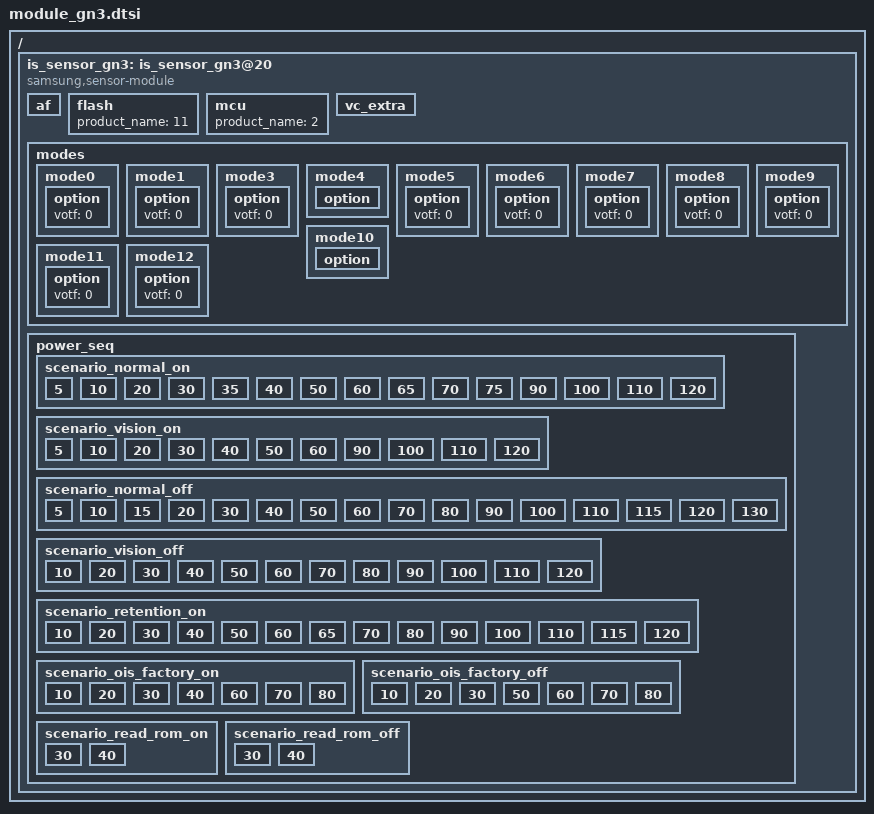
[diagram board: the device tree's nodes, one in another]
/*
 * SAMSUNG EXYNOSxxxx board camera device tree source
 *
 * Copyright (c) 2019 Samsung Electronics Co., Ltd.
 *		http://www.samsung.com
 *
 * This program is free software; you can redistribute it and/or modify
 * it under the terms of the GNU General Public License version 2 as
 * published by the Free Software Foundation.
 */

#include <dt-bindings/camera/exynos_is_dt.h>

/ {
	fragment@camera {
		target-path = "/";
		__overlay__ {
			is_sensor_gn3: is_sensor_gn3@20 {
				compatible = "samsung,sensor-module";

				/* common */
				sensor_id = <SENSOR_NAME_S5KGN3>;
				active_width = <8160>;
				active_height = <6144>;
				margin_left = <0>;
				margin_right = <0>;
				margin_top = <0>;
				margin_bottom = <0>;
				max_framerate = <480>;
				bitwidth = <10>;
				use_retention_mode = <SENSOR_RETENTION_INACTIVE>;
				sensor_maker = "SLSI";
				sensor_name = "S5KGN3";
				setfile_name = "setfile_gn3.bin";

				status = "okay";

				/* board */
				pinctrl-names = "pin0", "pin1", "pin2", "release";
				pinctrl-0 = <>;
				pinctrl-1 = <&sensor_mclk2_out>;
				pinctrl-2 = <&sensor_mclk2_fn>;
				pinctrl-3 = <>;

				position = <0>;	/* Rear:0. Front:1. Rear_sub:2. Secure:3. */
				id = <0>; /* is_sensor id */
				mclk_ch = <2>;
				mclk_freq = <19200>;
				sensor_i2c_ch = <0>; /* SENSOR_CONTROL_I2C0 */

				/* vendor */
				rom_type = <2>; /* ROM_TYPE_EEPROM */
				rom_id = <0>;
				rom_cal_index = <0>;

				/* peri */
				af {
					product_name = <18>; /* ACTUATOR_NAME_AK737X */
					i2c_ch = <1>; /* SENSOR_CONTROL_I2C1 */
				};

				flash {
					product_name = <11>; /* FLASH_GPIO */
				};

				mcu {
					product_name = <2>; /* INTERNAL */
				};

				vc_extra {
					/* ex) statX = <stat_type, sensor_mode, max_width, max_height, max_element> */
					stat0 = </* not available */>;									/* VC_BUF_DATA_TYPE_SENSOR_STAT1 */
					stat1 = </*VC_STAT_TYPE_PDP_4_0_PDAF_STAT0*/ 1100 /*VC_SENSOR_MODE_2PD_MODE3*/ 102 4080 764 2>;	/* VC_BUF_DATA_TYPE_GENERAL_STAT1 */
					stat2 = </* not available */>;									/* VC_BUF_DATA_TYPE_SENSOR_STAT2 */
					stat3 = </*VC_STAT_TYPE_PDP_4_0_PDAF_STAT1*/ 1101 /*VC_SENSOR_MODE_2PD_MODE3*/ 102 4080 764 2>;	/* VC_BUF_DATA_TYPE_GENERAL_STAT2 */
				};

				/* sensor modes
				*	SENSOR_GN3_8160X6120_27FPS = 0,
				*	SENSOR_GN3_4896X3672_30FPS_RAW12 = 1,
				*	SENSOR_GN3_7680X4320_30FPS = 2,
				*	SENSOR_GN3_7680X4320_30FPS_MPC = 3,
				*	SENSOR_GN3_4080X3060_60FPS_RAW12_FRO = 4,
				*	SENSOR_GN3_4080X3060_60FPS_RAW12 = 5,
				*	SENSOR_GN3_3328X1872_120FPS = 6,
				*	SENSOR_GN3_4080X2296_60FPS_RAW12 = 7,
				*	SENSOR_GN3_2040X1148_240FPS = 8,
				*	SENSOR_GN3_2040X1148_480FPS_MODE2 = 9,
				*	SENSOR_GN3_2040X1532_120FPS = 10,
				*	SENSOR_GN3_2800X2100_60FPS = 11,
				*	SENSOR_GN3_4080X2720_60FPS_RAW12 = 12,
				*/
				modes {
						/* common = <width, height, fps, settle, mode, lane, speed, interleave, lrte, pd_mode> */
						/* vcX = <map, hwformat, width, height, hwformat, type, width, height> */
					mode0 {
						common = <8160 6120 27 0 0 CSI_DATA_LANES_3 3046 CSI_MODE_VC_DT LRTE_ENABLE PD_MOD3>;
						vc0 = </* in */ 0 HW_FORMAT_RAW10 8160 6120	/* out */ HW_FORMAT_RAW10 VC_NOTHING 8160 6120>;
						vc1 = </* in */ 1 HW_FORMAT_UNKNOWN 0 0		/* out */ HW_FORMAT_UNKNOWN VC_NOTHING 0 0>;
						vc2 = </* in */ 2 HW_FORMAT_RAW10 4080 764	/* out */ HW_FORMAT_RAW10 VC_NOTHING 0 0>;
						vc3 = </* in */ 3 HW_FORMAT_UNKNOWN 0 0		/* out */ HW_FORMAT_UNKNOWN VC_NOTHING 0 0>;
						option { votf = <0>; };
					};

					mode1 {
						common = <4896 3672 30 0 1 CSI_DATA_LANES_3 3315 CSI_MODE_VC_DT LRTE_ENABLE PD_MOD3>;
						vc0 = </* in */ 0 HW_FORMAT_RAW12 4896 3672	/* out */ HW_FORMAT_RAW12 VC_NOTHING 4896 3672>;
						vc1 = </* in */ 1 HW_FORMAT_UNKNOWN 0 0		/* out */ HW_FORMAT_UNKNOWN VC_NOTHING 0 0>;
						vc2 = </* in */ 2 HW_FORMAT_RAW10 2448 458	/* out */ HW_FORMAT_RAW10 VC_NOTHING 0 0>;
						vc3 = </* in */ 3 HW_FORMAT_UNKNOWN 0 0		/* out */ HW_FORMAT_UNKNOWN VC_NOTHING 0 0>;
						option { votf = <0>; };
					};

					mode3 { /* MPC */
						common = <7680 4320 30 0 3 CSI_DATA_LANES_3 2585 CSI_MODE_VC_DT LRTE_DISABLE PD_MOD3>;
						vc0 = </* in */ 0 HW_FORMAT_RAW10 7680 4320	/* out */ HW_FORMAT_RAW10 VC_NOTHING 7680 4320>;
						vc1 = </* in */ 1 HW_FORMAT_UNKNOWN 0 0		/* out */ HW_FORMAT_UNKNOWN VC_NOTHING 0 0>;
						vc2 = </* in */ 2 HW_FORMAT_RAW10 3840 540	/* out */ HW_FORMAT_RAW10 VC_NOTHING 0 0>;
						vc3 = </* in */ 3 HW_FORMAT_UNKNOWN 0 0		/* out */ HW_FORMAT_UNKNOWN VC_NOTHING 0 0>;
						option { votf = <0>; };
					};

					mode4 { /* FRO */
						common = <4080 3060 60 0 4 CSI_DATA_LANES_3 3315 CSI_MODE_VC_DT LRTE_ENABLE PD_MOD3 EX_12BIT>;
						vc0 = </* in */ 0 HW_FORMAT_RAW12 4080 3060	/* out */ HW_FORMAT_RAW12 VC_NOTHING 4080 3060>;
						vc1 = </* in */ 1 HW_FORMAT_UNKNOWN 0 0		/* out */ HW_FORMAT_UNKNOWN VC_NOTHING 0 0>;
						vc2 = </* in */ 2 HW_FORMAT_RAW10 4080 764	/* out */ HW_FORMAT_RAW10 VC_NOTHING 0 0>;
						vc3 = </* in */ 3 HW_FORMAT_UNKNOWN 0 0		/* out */ HW_FORMAT_UNKNOWN VC_NOTHING 0 0>;
						option { votf = <0>; vvalid_time = <8736>; req_vvalid_time = <10000>; };// mpc_mode = <2> };
					};

					mode5 {
						common = <4080 3060 60 0 5 CSI_DATA_LANES_3 3315 CSI_MODE_VC_DT LRTE_ENABLE PD_MOD3>;
						vc0 = </* in */ 0 HW_FORMAT_RAW10 4080 3060	/* out */ HW_FORMAT_RAW10 VC_NOTHING 4080 3060>;
						vc1 = </* in */ 1 HW_FORMAT_UNKNOWN 0 0		/* out */ HW_FORMAT_UNKNOWN VC_NOTHING 0 0>;
						vc2 = </* in */ 2 HW_FORMAT_RAW10 4080 764	/* out */ HW_FORMAT_RAW10 VC_NOTHING 0 0>;
						vc3 = </* in */ 3 HW_FORMAT_UNKNOWN 0 0		/* out */ HW_FORMAT_UNKNOWN VC_NOTHING 0 0>;
						option { votf = <0>; };
					};

					mode6 {
						common = <3328 1872 120 0 6 CSI_DATA_LANES_3 3046 CSI_MODE_VC_DT LRTE_ENABLE PD_MOD3>;
						vc0 = </* in */ 0 HW_FORMAT_RAW10 3328 1872	/* out */ HW_FORMAT_RAW10 VC_NOTHING 3328 1872>;
						vc1 = </* in */ 1 HW_FORMAT_UNKNOWN 0 0		/* out */ HW_FORMAT_UNKNOWN VC_NOTHING 0 0>;
						vc2 = </* in */ 2 HW_FORMAT_RAW10 3328 468	/* out */ HW_FORMAT_RAW10 VC_NOTHING 0 0>;
						vc3 = </* in */ 3 HW_FORMAT_UNKNOWN 0 0		/* out */ HW_FORMAT_UNKNOWN VC_NOTHING 0 0>;
						option { votf = <0>; };
					};

					mode7 {
						common = <4080 2296 60 0 7 CSI_DATA_LANES_3 3315 CSI_MODE_VC_DT LRTE_ENABLE PD_MOD3>;
						vc0 = </* in */ 0 HW_FORMAT_RAW12 4080 2296	/* out */ HW_FORMAT_RAW12 VC_NOTHING 4080 2296>;
						vc1 = </* in */ 1 HW_FORMAT_UNKNOWN 0 0		/* out */ HW_FORMAT_UNKNOWN VC_NOTHING 0 0>;
						vc2 = </* in */ 2 HW_FORMAT_RAW10 4080 574	/* out */ HW_FORMAT_RAW10 VC_NOTHING 0 0>;
						vc3 = </* in */ 3 HW_FORMAT_UNKNOWN 0 0		/* out */ HW_FORMAT_UNKNOWN VC_NOTHING 0 0>;
						option { votf = <0>; };
					};

					mode8 {
						common = <2040 1148 240 0 8 CSI_DATA_LANES_3 2585 CSI_MODE_VC_DT LRTE_ENABLE PD_MOD3>;
						vc0 = </* in */ 0 HW_FORMAT_RAW10 2040 1148	/* out */ HW_FORMAT_RAW10 VC_NOTHING 2040 1148>;
						vc1 = </* in */ 1 HW_FORMAT_UNKNOWN 0 0		/* out */ HW_FORMAT_UNKNOWN VC_NOTHING 0 0>;
						vc2 = </* in */ 2 HW_FORMAT_RAW10 2032 286	/* out */ HW_FORMAT_RAW10 VC_NOTHING 0 0>;
						vc3 = </* in */ 3 HW_FORMAT_UNKNOWN 0 0		/* out */ HW_FORMAT_UNKNOWN VC_NOTHING 0 0>;
						option { votf = <0>; };
					};

					mode9 {
						common = <2040 1148 480 0 9 CSI_DATA_LANES_3 2585 CSI_MODE_VC_DT LRTE_ENABLE PD_MOD2>;
						vc0 = </* in */ 0 HW_FORMAT_RAW10 2040 1148	/* out */ HW_FORMAT_RAW10 VC_NOTHING 2040 1148>;
						vc1 = </* in */ 1 HW_FORMAT_UNKNOWN 0 0		/* out */ HW_FORMAT_UNKNOWN VC_NOTHING 0 0>;
						vc2 = </* in */ 2 HW_FORMAT_UNKNOWN 0 0		/* out */ HW_FORMAT_UNKNOWN VC_NOTHING 0 0>;
						vc3 = </* in */ 3 HW_FORMAT_UNKNOWN 0 0		/* out */ HW_FORMAT_UNKNOWN VC_NOTHING 0 0>;
						option { votf = <0>; };
					};

					mode10 {
						common = <2040 1532 120 0 10 CSI_DATA_LANES_3 2585 CSI_MODE_VC_DT LRTE_ENABLE PD_NONE>;
						vc0 = </* in */ 0 HW_FORMAT_RAW10 2040 1532	/* out */ HW_FORMAT_RAW10 VC_NOTHING 2040 1532>;
						vc1 = </* in */ 1 HW_FORMAT_UNKNOWN 0 0		/* out */ HW_FORMAT_UNKNOWN VC_NOTHING 0 0>;
						vc2 = </* in */ 2 HW_FORMAT_UNKNOWN 0 0		/* out */ HW_FORMAT_UNKNOWN VC_NOTHING 0 0>;
						vc3 = </* in */ 3 HW_FORMAT_UNKNOWN 0 0		/* out */ HW_FORMAT_UNKNOWN VC_NOTHING 0 0>;
						option { votf = <0>; special_mode = <IS_SPECIAL_MODE_FASTAE>; };
					};

					mode11 {
						common = <2800 2100 60 0 11 CSI_DATA_LANES_3 3046 CSI_MODE_VC_DT LRTE_ENABLE PD_MOD3>;
						vc0 = </* in */ 0 HW_FORMAT_RAW10 2800 2100	/* out */ HW_FORMAT_RAW10 VC_NOTHING 2800 2100>;
						vc1 = </* in */ 1 HW_FORMAT_UNKNOWN 0 0		/* out */ HW_FORMAT_UNKNOWN VC_NOTHING 0 0>;
						vc2 = </* in */ 2 HW_FORMAT_RAW10 2800 524	/* out */ HW_FORMAT_RAW10 VC_NOTHING 0 0>;
						vc3 = </* in */ 3 HW_FORMAT_UNKNOWN 0 0		/* out */ HW_FORMAT_UNKNOWN VC_NOTHING 0 0>;
						option { votf = <0>; };
					};

					mode12 {
						common = <4080 2720 60 0 12 CSI_DATA_LANES_3 3315 CSI_MODE_VC_DT LRTE_ENABLE PD_MOD3>;
						vc0 = </* in */ 0 HW_FORMAT_RAW12 4080 2720	/* out */ HW_FORMAT_RAW12 VC_NOTHING 4080 2720>;
						vc1 = </* in */ 1 HW_FORMAT_UNKNOWN 0 0		/* out */ HW_FORMAT_UNKNOWN VC_NOTHING 0 0>;
						vc2 = </* in */ 2 HW_FORMAT_RAW10 4080 680	/* out */ HW_FORMAT_RAW10 VC_NOTHING 0 0>;
						vc3 = </* in */ 3 HW_FORMAT_UNKNOWN 0 0		/* out */ HW_FORMAT_UNKNOWN VC_NOTHING 0 0>;
						option { votf = <0>; };
					};
				};



				power_seq {
					use = <1>;
					gpio_mclk = <&gpg1 2 0x1>;
					scenario_normal_on {
						sensor_scenario = <SENSOR_SCENARIO_NORMAL>;
						gpio_scenario = <GPIO_SCENARIO_ON>;

						/* A start node number should be over the 10 for reserved number 0~9. */
						/* pname = "name"; pin = <act value delay voltage>; gpio = <gpx# # 0x1>; */
						5 { pname = "S2MPB02_BUCK2"; pin = <PIN_REGULATOR 1 0>; share = <SRT_ACQUIRE SHARED_PIN0 1>; };
						10 { pname = "sen_rst low"; pin = <PIN_OUTPUT 0 0>; gpio = <&gpc0 0 0x1>; };
						20 { pname = "VDDD_2.8V_OIS"; pin = <PIN_REGULATOR 1 300>; };
						30 { pname = "VDDIO_1.8V_CAM"; pin = <PIN_REGULATOR 1 0>; share = <SRT_ACQUIRE SHARED_PIN2 1>; };
						35 { pname = "VDDIO_1.8V_SUB"; pin = <PIN_REGULATOR 1 0>; share = <SRT_ACQUIRE SHARED_PIN1 1>; };
						40 { pname = "VDDPHY_1.05V_CAM"; pin = <PIN_REGULATOR 1 0>; };
						50 { pname = "S2MPB02_BUCK1"; pin = <PIN_REGULATOR 1 1>; };
						60 { pname = "VDDAF_COMMON_CAM"; pin = <PIN_REGULATOR 1 1>; share = <SRT_ACQUIRE SHARED_PIN4 1>; };
						65 { pname = "VDDAF_2.8V_SUB"; pin = <PIN_REGULATOR 1 0>; share = <SRT_ACQUIRE SHARED_PIN5 1>; };
						70 { pname = "VDDA_2.8V_CAM"; pin = <PIN_REGULATOR 1 100>; share = <SRT_ACQUIRE SHARED_PIN6 1>; };
						75 { pname = "S2MPB02_LD10"; pin = <PIN_REGULATOR 1 0>; share = <SRT_ACQUIRE SHARED_PIN7 1>; };
						//80 { pname = "VDDOIS_2.8V_SUB"; pin = <PIN_REGULATOR 1 0>; share = <SRT_ACQUIRE SHARED_PIN3 1>; };

						90 { pname = "on_i2c"; pin = <PIN_I2C 1 0>; };
						100 { pname = "pin"; pin = <PIN_FUNCTION 2 0>; };
						110 { pname = "MCLK"; pin = <PIN_MCLK 1 1500>; };
						120 { pname = "sen_rst high"; pin = <PIN_OUTPUT 1 3000>; gpio = <&gpc0 0 0x1>; };
					};

					scenario_vision_on {
						sensor_scenario = <SENSOR_SCENARIO_VISION>;
						gpio_scenario = <GPIO_SCENARIO_ON>;

						/* A start node number should be over the 10 for reserved number 0~9. */
						/* pname = "name"; pin = <act value delay voltage>; gpio = <gpx# # 0x1>; */
						5 { pname = "S2MPB02_BUCK2"; pin = <PIN_REGULATOR 1 0>; };
						10 { pname = "sen_rst low"; pin = <PIN_OUTPUT 0 0>; gpio = <&gpc0 0 0x1>; };
						20 { pname = "VDDD_2.8V_OIS"; pin = <PIN_REGULATOR 1 0>; };
						30 { pname = "VDDIO_1.8V_CAM"; pin = <PIN_REGULATOR 1 300>; };
						40 { pname = "VDDPHY_1.05V_CAM"; pin = <PIN_REGULATOR 1 0>; };
						50 { pname = "S2MPB02_BUCK1"; pin = <PIN_REGULATOR 1 1>; };
						60 { pname = "VDDAF_COMMON_CAM"; pin = <PIN_REGULATOR 1 1>; };

						90 { pname = "on_i2c"; pin = <PIN_I2C 1 0>; };
						100 { pname = "pin"; pin = <PIN_FUNCTION 2 0>; };
						110 { pname = "MCLK"; pin = <PIN_MCLK 1 1500>; };
						120 { pname = "sen_rst high"; pin = <PIN_OUTPUT 1 3000>; gpio = <&gpc0 0 0x1>; };
					};

					scenario_normal_off {
						sensor_scenario = <SENSOR_SCENARIO_NORMAL>;
						gpio_scenario = <GPIO_SCENARIO_OFF>;

						/* A start node number should be over the 10 for reserved number 0~9. */
						/* pname = "name"; pin = <act value delay voltage>; gpio = <gpx# # 0x1>; */
						5 { pname = "sen_rst low"; pin = <PIN_OUTPUT 0 10>; gpio = <&gpc0 0 0x1>; };
						10 { pname = "VDDAF_COMMON_CAM"; pin = <PIN_REGULATOR 0 10>; share = <SRT_RELEASE SHARED_PIN4 0>; };
						15 { pname = "VDDAF_2.8V_SUB"; pin = <PIN_REGULATOR 0 10>; share = <SRT_RELEASE SHARED_PIN5 0>; };
						20 { pname = "VDDPHY_1.05V_CAM"; pin = <PIN_REGULATOR 0 0>; };
						30 { pname = "S2MPB02_BUCK1"; pin = <PIN_REGULATOR 0 10>; };
						40 { pname = "MCLK"; pin = <PIN_MCLK 0 0>; };
						50 { pname = "pin"; pin = <PIN_FUNCTION 0 0>; };
						60 { pname = "pin"; pin = <PIN_FUNCTION 1 0>; };
						70 { pname = "pin"; pin = <PIN_FUNCTION 0 0>; };
						80 { pname = "off_i2c"; pin = <PIN_I2C 0 0>; };
						//85 { pname = "VDDOIS_2.8V_SUB"; pin = <PIN_REGULATOR 0 0>; share = <SRT_RELEASE SHARED_PIN3 0>; };
						90 { pname = "S2MPB02_LD10"; pin = <PIN_REGULATOR 0 0>; share = <SRT_RELEASE SHARED_PIN7 0>; };
						100 { pname = "VDDA_2.8V_CAM"; pin = <PIN_REGULATOR 0 0>; share = <SRT_RELEASE SHARED_PIN6 0>; };
						110 { pname = "VDDIO_1.8V_CAM"; pin = <PIN_REGULATOR 0 10>; share = <SRT_RELEASE SHARED_PIN2 0>; };
						115 { pname = "VDDIO_1.8V_SUB"; pin = <PIN_REGULATOR 0 10>; share = <SRT_RELEASE SHARED_PIN1 0>; };
						120 { pname = "VDDD_2.8V_OIS"; pin = <PIN_REGULATOR 0 0>; };
						130 { pname = "S2MPB02_BUCK2"; pin = <PIN_REGULATOR 0 0>; share = <SRT_RELEASE SHARED_PIN0 0>; };
					};

					scenario_vision_off {
						sensor_scenario = <SENSOR_SCENARIO_VISION>;
						gpio_scenario = <GPIO_SCENARIO_OFF>;

						/* A start node number should be over the 10 for reserved number 0~9. */
						/* pname = "name"; pin = <act value delay voltage>; gpio = <gpx# # 0x1>; */

						/* A start node number should be over the 10 for reserved number 0~9. */
						/* pname = "name"; pin = <act value delay voltage>; gpio = <gpx# # 0x1>; */
						10 { pname = "VDDAF_COMMON_CAM"; pin = <PIN_REGULATOR 0 10>; };
						20 { pname = "VDDPHY_1.05V_CAM"; pin = <PIN_REGULATOR 0 0>; };
						30 { pname = "S2MPB02_BUCK1"; pin = <PIN_REGULATOR 0 10>; };
						40 { pname = "MCLK"; pin = <PIN_MCLK 0 0>; };
						50 { pname = "pin"; pin = <PIN_FUNCTION 0 0>; };
						60 { pname = "pin"; pin = <PIN_FUNCTION 1 0>; };
						70 { pname = "pin"; pin = <PIN_FUNCTION 0 0>; };
						80 { pname = "sen_rst low"; pin = <PIN_OUTPUT 0 10>; gpio = <&gpc0 0 0x1>; };
						90 { pname = "off_i2c"; pin = <PIN_I2C 0 0>; };
						100 { pname = "VDDIO_1.8V_CAM"; pin = <PIN_REGULATOR 0 10>; };
						110 { pname = "VDDD_2.8V_OIS"; pin = <PIN_REGULATOR 0 0>; };
						120 { pname = "S2MPB02_BUCK2"; pin = <PIN_REGULATOR 0 0>; };
					};

					scenario_retention_on {
						sensor_scenario = <SENSOR_SCENARIO_NORMAL>;
						gpio_scenario = <GPIO_SCENARIO_SENSOR_RETENTION_ON>;

						/* A start node number should be over the 10 for reserved number 0~9. */
						/* pname = "name"; pin = <act value delay voltage>; gpio = <gpx# # 0x1>; */
						10 { pname = "(retention) sen_rst low"; pin = <PIN_OUTPUT 0 10>; gpio = <&gpc0 0 0x1>; };
						20 { pname = "MCLK"; pin = <PIN_MCLK 0 0>; };
						30 { pname = "pin"; pin = <PIN_FUNCTION 0 0>; };
						40 { pname = "pin"; pin = <PIN_FUNCTION 1 0>; };
						50 { pname = "pin"; pin = <PIN_FUNCTION 0 0>; };
						60 { pname = "VDDAF_COMMON_CAM"; pin = <PIN_REGULATOR 0 10>; };
						65 { pname = "VDDAF_2.8V_SUB"; pin = <PIN_REGULATOR 0 10>; share = <SRT_RELEASE SHARED_PIN5 0>; };
						70 { pname = "VDDPHY_1.05V_CAM"; pin = <PIN_REGULATOR 0 0>; };
						80 { pname = "S2MPB02_BUCK1"; pin = <PIN_REGULATOR 0 10>; };
						90 { pname = "off_i2c"; pin = <PIN_I2C 0 0>; };
						//95 { pname = "VDDOIS_2.8V_SUB"; pin = <PIN_REGULATOR 0 0>; share = <SRT_RELEASE SHARED_PIN3 0>; };
						100 { pname = "S2MPB02_LD10"; pin = <PIN_REGULATOR 0 0>; share = <SRT_RELEASE SHARED_PIN7 0>; };
						110 { pname = "VDDA_2.8V_CAM"; pin = <PIN_REGULATOR 0 0>; share = <SRT_RELEASE SHARED_PIN6 0>; };
						115 { pname = "VDDIO_1.8V_SUB"; pin = <PIN_REGULATOR 0 10>; share = <SRT_RELEASE SHARED_PIN1 0>; };
						120 { pname = "S2MPB02_BUCK2"; pin = <PIN_REGULATOR 0 0>; share = <SRT_RELEASE SHARED_PIN0 0>; };
					};

					scenario_ois_factory_on {
						sensor_scenario = <SENSOR_SCENARIO_OIS_FACTORY>;
						gpio_scenario = <GPIO_SCENARIO_ON>;

						/* A start node number should be over the 10 for reserved number 0~9. */
						/* pname = "name"; pin = <act value delay voltage>; gpio = <gpx# # 0x1>; */
						10 { pname = "VDDIO_1.8V_CAM"; pin = <PIN_REGULATOR 1 300>; };
						20 { pname = "VDDAF_COMMON_CAM"; pin = <PIN_REGULATOR 1 0>; };
						30 { pname = "VDDAF_2.8V_SUB"; pin = <PIN_REGULATOR 1 0>; }; /* CAMERA_REAR2_AF */
						40 { pname = "VDDIO_1.8V_SUB"; pin = <PIN_REGULATOR 1 0>; } ;/* CAMERA_REAR2_AF */
						//50 { pname = "VDDOIS_2.8V_SUB"; pin = <PIN_REGULATOR 1 0>; };
						60 { pname = "VDDA_2.8V_CAM"; pin = <PIN_REGULATOR 1 0>; };
						70 { pname = "S2MPB02_LD10"; pin = <PIN_REGULATOR 1 0>; };
						80 { pname = "on_i2c"; pin = <PIN_I2C 1 10>; };
					};

					scenario_ois_factory_off {
						sensor_scenario = <SENSOR_SCENARIO_OIS_FACTORY>;
						gpio_scenario = <GPIO_SCENARIO_OFF>;

						/* A start node number should be over the 10 for reserved number 0~9. */
						/* pname = "name"; pin = <act value delay voltage>; gpio = <gpx# # 0x1>; */
						10 { pname = "off_i2c"; pin = <PIN_I2C 0 0>; };
						20 { pname = "VDDA_2.8V_CAM"; pin = <PIN_REGULATOR 0 0>; };
						30 { pname = "S2MPB02_LD10"; pin = <PIN_REGULATOR 0 0>; };
						//40 { pname = "VDDOIS_2.8V_SUB"; pin = <PIN_REGULATOR 0 0>; };
						50 { pname = "VDDAF_COMMON_CAM"; pin = <PIN_REGULATOR 0 0>; };
						60 { pname = "VDDAF_2.8V_SUB"; pin = <PIN_REGULATOR 0 0>; }; /* CAMERA_REAR2_AF */
						70 { pname = "VDDIO_1.8V_SUB"; pin = <PIN_REGULATOR 0 0>; }; /* CAMERA_REAR2_AF */
						80 { pname = "VDDIO_1.8V_CAM"; pin = <PIN_REGULATOR 0 10>; };
					};

					scenario_read_rom_on {
						sensor_scenario = <SENSOR_SCENARIO_READ_ROM>;
						gpio_scenario = <GPIO_SCENARIO_ON>;

						/* A start node number should be over the 10 for reserved number 0~9. */
						/* pname = "name"; pin = <act value delay voltage>; gpio = <gpx# # 0x1>; */
						30 { pname = "VDDIO_1.8V_CAM"; pin = <PIN_REGULATOR 1 1000>; };
						40 { pname = "on_i2c"; pin = <PIN_I2C 1 0>; };
					};

					scenario_read_rom_off {
						sensor_scenario = <SENSOR_SCENARIO_READ_ROM>;
						gpio_scenario = <GPIO_SCENARIO_OFF>;

						/* A start node number should be over the 10 for reserved number 0~9. */
						/* pname = "name"; pin = <act value delay voltage>; gpio = <gpx# # 0x1>; */
						30 { pname = "off_i2c"; pin = <PIN_I2C 0 0>; };
						40 { pname = "VDDIO_1.8V_CAM"; pin = <PIN_REGULATOR 0 10>; };
					};
				};
			};
		}; /* end of __overlay__ */
	}; /* end of fragment */
}; /* end of root */
